# EFR32MG29B230F1024CM40 register map
Vendor: Silicon Labs; Series: EFR32; File version: C
Registers are 32-bit, read-write, reset 0x0 unless marked. A register's access mark holds for its fields unless they carry their own. Offsets are from the block's base; [hi:lo] are bit positions; {n}, {i} and the like mark numbered series.

## PRS_NS — PRS_NS Registers
Base 0x50038000
Same registers: PRS_S 0x40038000
0x00 IPVERSION ro reset 0x8
  [31:0] IPVERSION — IP version ID
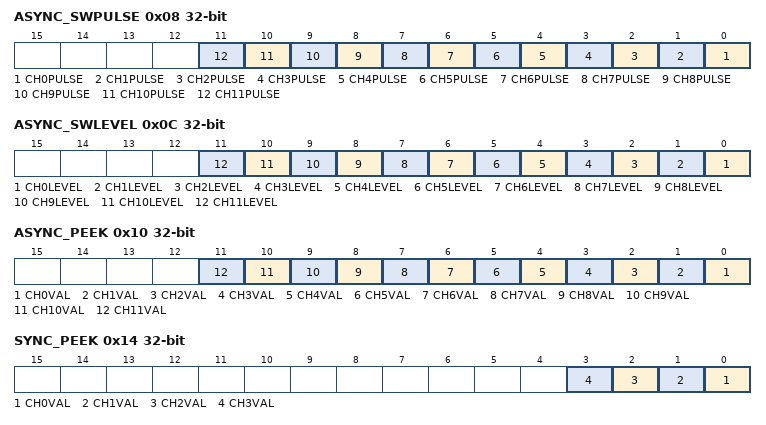
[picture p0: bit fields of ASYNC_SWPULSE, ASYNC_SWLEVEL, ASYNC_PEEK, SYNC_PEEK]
0x08 ASYNC_SWPULSE wo
  [n] CH{n}PULSE (n=0..11) — Channel pulse
0x0C ASYNC_SWLEVEL
  [n] CH{n}LEVEL (n=0..11) — Channel Level
0x10 ASYNC_PEEK ro
  [n] CH{n}VAL (n=0..11) — Channel {n} Current Value
0x14 SYNC_PEEK ro
  [n] CH{n}VAL (n=0..3) — Channel Value
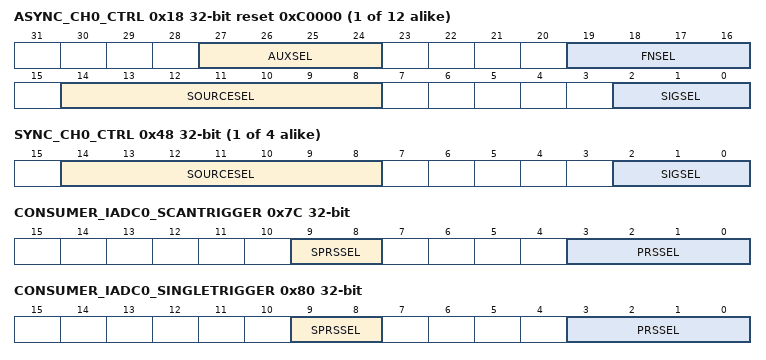
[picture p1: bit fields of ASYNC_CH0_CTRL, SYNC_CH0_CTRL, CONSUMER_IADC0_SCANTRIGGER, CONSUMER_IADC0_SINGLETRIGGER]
{0x18+4i} ASYNC_CH{i}_CTRL reset 0xC0000 (i=0..11)
  [27:24] AUXSEL — Auxiliary LUT Input Select
  [19:16] FNSEL — Function Select
    0=LOGICAL_ZERO (Logical 0); 1=A_NOR_B; 2=NOT_A_AND_B ((!A) AND B); 3=NOT_A (!A); 4=A_AND_NOT_B (A AND (!B)); 5=NOT_B (!B); 6=A_XOR_B; 7=A_NAND_B; 8=A_AND_B; 9=A_XNOR_B; 10=B; 11=NOT_A_OR_B ((!A) OR B); 12=A; 13=A_OR_NOT_B (A OR (!B)); 14=A_OR_B; 15=LOGICAL_ONE (Logical 1)
  [14:8] SOURCESEL — Source Select
  [2:0] SIGSEL — Signal Select
    0=NONE
{0x48+4i} SYNC_CH{i}_CTRL (i=0..3)
  [14:8] SOURCESEL — Source Select
  [2:0] SIGSEL — Signal Select
0x58 CONSUMER_CMU_CALDN — CALDN consumer register
  [3:0] PRSSEL — CALDN async channel select
0x5C CONSUMER_CMU_CALUP — CALUP Consumer register
  [3:0] PRSSEL — CALUP async channel select
0x60 CONSUMER_EUSART0_CLK — CLK consumer register
  [3:0] PRSSEL — CLK async channel select
0x64 CONSUMER_EUSART0_RX — RX Consumer register
  [3:0] PRSSEL — RX async channel select
0x68 CONSUMER_EUSART0_TRIGGER — TRIGGER Consumer register
  [3:0] PRSSEL — TRIGGER async channel select
0x6C CONSUMER_EUSART1_CLK — CLK consumer register
  [3:0] PRSSEL — CLK async channel select
0x70 CONSUMER_EUSART1_RX — RX Consumer register
  [3:0] PRSSEL — RX async channel select
0x74 CONSUMER_EUSART1_TRIGGER — TRIGGER Consumer register
  [3:0] PRSSEL — TRIGGER async channel select
0x7C CONSUMER_IADC0_SCANTRIGGER — SCAN consumer register
  [9:8] SPRSSEL — SCAN sync channel select
  [3:0] PRSSEL — SCAN async channel select
0x80 CONSUMER_IADC0_SINGLETRIGGER — SINGLE Consumer register
  [9:8] SPRSSEL — SINGLE sync channel select
  [3:0] PRSSEL — SINGLE async channel select
0x84 CONSUMER_LDMAXBAR_DMAREQ0 — DMAREQ0 consumer register
  [3:0] PRSSEL — DMAREQ0 async channel select
0x88 CONSUMER_LDMAXBAR_DMAREQ1 — DMAREQ1 Consumer register
  [3:0] PRSSEL — DMAREQ1 async channel select
0x8C CONSUMER_LETIMER0_CLEAR — CLEAR consumer register
  [3:0] PRSSEL — CLEAR async channel select
0x90 CONSUMER_LETIMER0_START — START Consumer register
  [3:0] PRSSEL — START async channel select
0x94 CONSUMER_LETIMER0_STOP — STOP Consumer register
  [3:0] PRSSEL — STOP async channel select
0x98 CONSUMER_MODEM_DIN — DIN consumer register
  [3:0] PRSSEL — DIN async channel select
0x9C CONSUMER_PRORTC_CC0 — CC0 consumer register
  [3:0] PRSSEL — CC0 async channel select
0xA0 CONSUMER_PRORTC_CC1 — CC1 Consumer register
  [3:0] PRSSEL — CC1 async channel select
0xD0 CONSUMER_RAC_CLR — CLR consumer register
  [3:0] PRSSEL — CLR async channel select
{0xD4+4i} CONSUMER_RAC_CTIIN{i} (i=0..3) — CTI Consumer register
  [3:0] PRSSEL — CTI async channel select
0xE4 CONSUMER_RAC_FORCETX — FORCETX Consumer register
  [3:0] PRSSEL — FORCETX async channel select
0xE8 CONSUMER_RAC_RXDIS — RXDIS Consumer register
  [3:0] PRSSEL — RXDIS async channel select
0xEC CONSUMER_RAC_RXEN — RXEN Consumer register
  [3:0] PRSSEL — RXEN async channel select
0xF0 CONSUMER_RAC_SEQ — SEQ Consumer register
  [3:0] PRSSEL — SEQ async channel select
0xF4 CONSUMER_RAC_TXEN — TXEN Consumer register
  [3:0] PRSSEL — TXEN async channel select
0xF8 CONSUMER_RTCC_CC0 — CC0 consumer register
  [3:0] PRSSEL — CC0 async channel select
0xFC CONSUMER_RTCC_CC1 — CC1 Consumer register
  [3:0] PRSSEL — CC1 async channel select
0x100 CONSUMER_RTCC_CC2 — CC2 Consumer register
  [3:0] PRSSEL — CC2 async channel select
0x108 CONSUMER_SETAMPER_TAMPERSRC26 — TAMPERSRC26 consumer register
  [3:0] PRSSEL — TAMPERSRC26 async channel select
{0xA0+4i} CONSUMER_SETAMPER_TAMPERSRC{i} (i=27..31) — TAMPERSRC{i} Consumer register
  [3:0] PRSSEL — TAMPERSRC{i} async channel select
0x120 CONSUMER_CORE_CTIIN0 — CTI0 consumer register
  [3:0] PRSSEL — CTI async channel select
{0x120+4i} CONSUMER_CORE_CTIIN{i} (i=1..3) — CTI{i} Consumer register
  [3:0] PRSSEL — CTI async channel select
0x130 CONSUMER_CORE_M33RXEV — M33 Consumer register
  [3:0] PRSSEL — M33 async channel select
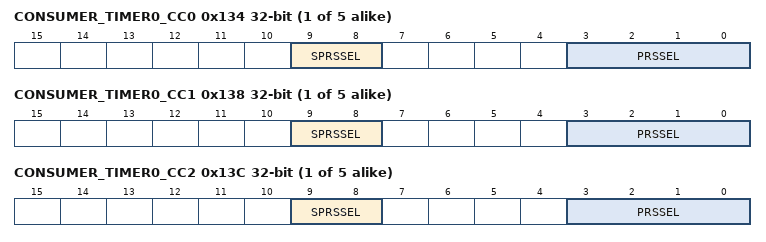
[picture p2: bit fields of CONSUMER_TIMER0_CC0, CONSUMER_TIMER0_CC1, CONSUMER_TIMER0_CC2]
{0x134+0x18*i} CONSUMER_TIMER{i}_CC0 (i=0..4) — CC0 consumer register
  [9:8] SPRSSEL — CC0 sync channel select
  [3:0] PRSSEL — CC0 async channel select
{0x138+0x18*i} CONSUMER_TIMER{i}_CC1 (i=0..4) — CC1 Consumer register
  [9:8] SPRSSEL — CC1 sync channel select
  [3:0] PRSSEL — CC1 async channel select
{0x13C+0x18*i} CONSUMER_TIMER{i}_CC2 (i=0..4) — CC2 Consumer register
  [9:8] SPRSSEL — CC2 sync channel select
  [3:0] PRSSEL — CC2 async channel select
{0x140+0x18*i} CONSUMER_TIMER{i}_DTI (i=0..4) — DTI Consumer register
  [3:0] PRSSEL — DTI async channel select
{0x144+0x18*i} CONSUMER_TIMER{i}_DTIFS1 (i=0..4) — DTI Consumer register
  [3:0] PRSSEL — DTI async channel select
{0x148+0x18*i} CONSUMER_TIMER{i}_DTIFS2 (i=0..4) — DTI Consumer register
  [3:0] PRSSEL — DTI async channel select
0x1AC CONSUMER_USART0_CLK — CLK consumer register
  [3:0] PRSSEL — CLK async channel select
0x1B0 CONSUMER_USART0_IR — IR Consumer register
  [3:0] PRSSEL — IR async channel select
0x1B4 CONSUMER_USART0_RX — RX Consumer register
  [3:0] PRSSEL — RX async channel select
0x1B8 CONSUMER_USART0_TRIGGER — TRIGGER Consumer register
  [3:0] PRSSEL — TRIGGER async channel select
0x1C8 CONSUMER_USART1_CLK — CLK consumer register
  [3:0] PRSSEL — CLK async channel select
0x1CC CONSUMER_USART1_IR — IR Consumer register
  [3:0] PRSSEL — IR async channel select
0x1D0 CONSUMER_USART1_RX — RX Consumer register
  [3:0] PRSSEL — RX async channel select
0x1D4 CONSUMER_USART1_TRIGGER — TRIGGER Consumer register
  [3:0] PRSSEL — TRIGGER async channel select
0x1E4 CONSUMER_WDOG0_SRC0 — SRC0 consumer register
  [3:0] PRSSEL — SRC0 async channel select
0x1E8 CONSUMER_WDOG0_SRC1 — SRC1 Consumer register
  [3:0] PRSSEL — SRC1 async channel select
